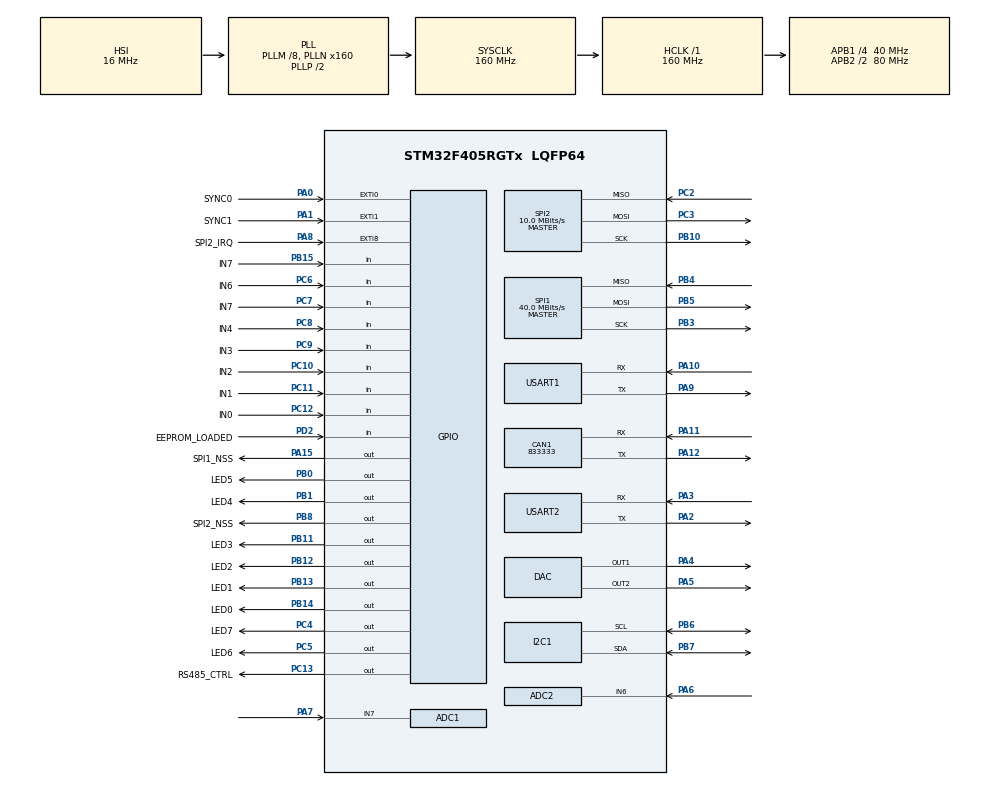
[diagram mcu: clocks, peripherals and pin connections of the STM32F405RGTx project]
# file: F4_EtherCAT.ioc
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ADC1.Channel-0\#ChannelRegularConversion=ADC_CHANNEL_7
ADC1.DMAContinuousRequests=ENABLE
ADC1.ExternalTrigConv=ADC_EXTERNALTRIGCONV_T2_TRGO
ADC1.NbrOfConversionFlag=1
ADC1.Rank-0\#ChannelRegularConversion=1
ADC1.SamplingTime-0\#ChannelRegularConversion=ADC_SAMPLETIME_15CYCLES
ADC1.master=1
ADC2.Channel-0\#ChannelRegularConversion=ADC_CHANNEL_6
ADC2.DMAContinuousRequests=ENABLE
ADC2.ExternalTrigConv=ADC_EXTERNALTRIGCONV_T2_TRGO
ADC2.NbrOfConversionFlag=1
ADC2.Rank-0\#ChannelRegularConversion=1
ADC2.SamplingTime-0\#ChannelRegularConversion=ADC_SAMPLETIME_15CYCLES
CAN1.BS1=CAN_BS1_1TQ
CAN1.BS2=CAN_BS2_1TQ
CAN1.CalculateBaudRate=833333
CAN1.CalculateTimeBit=1200.00
CAN1.CalculateTimeQuantum=400.0
DAC.DAC_Trigger=DAC_TRIGGER_T2_TRGO
DAC.DAC_Trigger2=DAC_TRIGGER_T2_TRGO
Dma.ADC1.0.Direction=DMA_PERIPH_TO_MEMORY
Dma.ADC1.0.FIFOMode=DMA_FIFOMODE_DISABLE
Dma.ADC1.0.Instance=DMA2_Stream0
Dma.ADC1.0.MemDataAlignment=DMA_MDATAALIGN_HALFWORD
Dma.ADC1.0.MemInc=DMA_MINC_ENABLE
Dma.ADC1.0.Mode=DMA_CIRCULAR
Dma.ADC1.0.PeriphDataAlignment=DMA_PDATAALIGN_HALFWORD
Dma.ADC1.0.PeriphInc=DMA_PINC_DISABLE
Dma.ADC1.0.Priority=DMA_PRIORITY_LOW
Dma.ADC2.1.Direction=DMA_PERIPH_TO_MEMORY
Dma.ADC2.1.FIFOMode=DMA_FIFOMODE_DISABLE
Dma.ADC2.1.Instance=DMA2_Stream2
Dma.ADC2.1.MemDataAlignment=DMA_MDATAALIGN_HALFWORD
Dma.ADC2.1.MemInc=DMA_MINC_ENABLE
Dma.ADC2.1.Mode=DMA_CIRCULAR
Dma.ADC2.1.PeriphDataAlignment=DMA_PDATAALIGN_HALFWORD
Dma.ADC2.1.PeriphInc=DMA_PINC_DISABLE
Dma.ADC2.1.Priority=DMA_PRIORITY_LOW
Dma.DAC1.2.Direction=DMA_MEMORY_TO_PERIPH
Dma.DAC1.2.FIFOMode=DMA_FIFOMODE_DISABLE
Dma.DAC1.2.Instance=DMA1_Stream5
Dma.DAC1.2.MemDataAlignment=DMA_MDATAALIGN_HALFWORD
Dma.DAC1.2.MemInc=DMA_MINC_ENABLE
Dma.DAC1.2.Mode=DMA_CIRCULAR
Dma.DAC1.2.PeriphDataAlignment=DMA_PDATAALIGN_HALFWORD
Dma.DAC1.2.PeriphInc=DMA_PINC_DISABLE
Dma.DAC1.2.Priority=DMA_PRIORITY_LOW
Dma.DAC2.3.Direction=DMA_MEMORY_TO_PERIPH
Dma.DAC2.3.FIFOMode=DMA_FIFOMODE_DISABLE
Dma.DAC2.3.Instance=DMA1_Stream6
Dma.DAC2.3.MemDataAlignment=DMA_MDATAALIGN_HALFWORD
Dma.DAC2.3.MemInc=DMA_MINC_ENABLE
Dma.DAC2.3.Mode=DMA_CIRCULAR
Dma.DAC2.3.PeriphDataAlignment=DMA_PDATAALIGN_HALFWORD
Dma.DAC2.3.PeriphInc=DMA_PINC_DISABLE
Dma.DAC2.3.Priority=DMA_PRIORITY_LOW
Dma.Request0=ADC1
Dma.Request1=ADC2
Dma.Request2=DAC1
Dma.Request3=DAC2
Mcu.Family=STM32F4
Mcu.Name=STM32F405RGTx
Mcu.Package=LQFP64
NVIC.DMA1_Stream5_IRQn=true\:0\:0\:false\:false\:true\:false\:true
NVIC.DMA1_Stream6_IRQn=true\:0\:0\:false\:false\:true\:false\:true
NVIC.DMA2_Stream0_IRQn=true\:0\:0\:false\:false\:true\:false\:true
NVIC.DMA2_Stream2_IRQn=true\:0\:0\:false\:false\:true\:false\:true
NVIC.EXTI0_IRQn=true\:0\:0\:false\:false\:false\:true\:true
NVIC.EXTI1_IRQn=true\:0\:0\:false\:false\:false\:true\:true
NVIC.EXTI9_5_IRQn=true\:0\:0\:false\:false\:false\:true\:true
NVIC.PriorityGroup=NVIC_PRIORITYGROUP_4
NVIC.TIM2_IRQn=true\:0\:0\:false\:false\:false\:true\:true
PA0-WKUP.GPIO_Label=SYNC0
PA0-WKUP.GPIO_ModeDefaultEXTI=GPIO_MODE_IT_FALLING
PA0-WKUP.Signal=GPXTI0
PA1.GPIO_Label=SYNC1
PA1.GPIO_ModeDefaultEXTI=GPIO_MODE_IT_FALLING
PA1.Signal=GPXTI1
PA10.Mode=Asynchronous
PA10.Signal=USART1_RX
PA11.Mode=CAN_Activate
PA11.Signal=CAN1_RX
PA12.Mode=CAN_Activate
PA12.Signal=CAN1_TX
PA13.Mode=Serial_Wire
PA13.Signal=SYS_JTMS-SWDIO
PA14.Mode=Serial_Wire
PA14.Signal=SYS_JTCK-SWCLK
PA15.GPIO_Label=SPI1_NSS
PA15.GPIO_Speed=GPIO_SPEED_FREQ_VERY_HIGH
PA15.Signal=GPIO_Output
PA2.Mode=Asynchronous
PA2.Signal=USART2_TX
PA3.Mode=Asynchronous
PA3.Signal=USART2_RX
PA4.Signal=COMP_DAC1_group
PA5.Signal=COMP_DAC2_group
PA6.Signal=ADCx_IN6
PA7.Signal=ADCx_IN7
PA8.GPIO_Label=SPI2_IRQ
PA8.GPIO_ModeDefaultEXTI=GPIO_MODE_IT_FALLING
PA8.Signal=GPXTI8
PA9.Mode=Asynchronous
PA9.Signal=USART1_TX
PB0.GPIO_Label=LED5
PB0.GPIO_Speed=GPIO_SPEED_FREQ_VERY_HIGH
PB0.Signal=GPIO_Output
PB1.GPIO_Label=LED4
PB1.GPIO_Speed=GPIO_SPEED_FREQ_VERY_HIGH
PB1.Signal=GPIO_Output
PB10.Mode=Full_Duplex_Master
PB10.Signal=SPI2_SCK
PB11.GPIO_Label=LED3
PB11.GPIO_Speed=GPIO_SPEED_FREQ_VERY_HIGH
PB11.Signal=GPIO_Output
PB12.GPIO_Label=LED2
PB12.GPIO_Speed=GPIO_SPEED_FREQ_VERY_HIGH
PB12.Signal=GPIO_Output
PB13.GPIO_Label=LED1
PB13.GPIO_Speed=GPIO_SPEED_FREQ_VERY_HIGH
PB13.Signal=GPIO_Output
PB14.GPIO_Label=LED0
PB14.GPIO_Speed=GPIO_SPEED_FREQ_VERY_HIGH
PB14.Signal=GPIO_Output
PB15.GPIO_Label=IN7
PB15.GPIO_PuPd=GPIO_PULLDOWN
PB15.Signal=GPIO_Input
PB3.Mode=Full_Duplex_Master
PB3.Signal=SPI1_SCK
PB4.Mode=Full_Duplex_Master
PB4.Signal=SPI1_MISO
PB5.Mode=Full_Duplex_Master
PB5.Signal=SPI1_MOSI
PB6.Mode=I2C
PB6.Signal=I2C1_SCL
PB7.Mode=I2C
PB7.Signal=I2C1_SDA
PB8.GPIO_Label=SPI2_NSS
PB8.GPIO_Speed=GPIO_SPEED_FREQ_VERY_HIGH
PB8.Signal=GPIO_Output
PC10.GPIO_Label=IN2
PC10.GPIO_PuPd=GPIO_PULLDOWN
PC10.Signal=GPIO_Input
PC11.GPIO_Label=IN1
PC11.GPIO_PuPd=GPIO_PULLDOWN
PC11.Signal=GPIO_Input
PC12.GPIO_Label=IN0
PC12.GPIO_PuPd=GPIO_PULLDOWN
PC12.Signal=GPIO_Input
PC13-ANTI_TAMP.GPIO_Label=RS485_CTRL
PC13-ANTI_TAMP.Signal=GPIO_Output
PC2.Mode=Full_Duplex_Master
PC2.Signal=SPI2_MISO
PC3.Mode=Full_Duplex_Master
PC3.Signal=SPI2_MOSI
PC4.GPIO_Label=LED7
PC4.GPIO_Speed=GPIO_SPEED_FREQ_VERY_HIGH
PC4.Signal=GPIO_Output
PC5.GPIO_Label=LED6
PC5.GPIO_Speed=GPIO_SPEED_FREQ_VERY_HIGH
PC5.Signal=GPIO_Output
PC6.GPIO_Label=IN6
PC6.GPIO_PuPd=GPIO_PULLDOWN
PC6.Signal=GPIO_Input
PC7.GPIO_Label=IN7
PC7.GPIO_PuPd=GPIO_PULLDOWN
PC7.Signal=GPIO_Input
PC8.GPIO_Label=IN4
PC8.GPIO_PuPd=GPIO_PULLDOWN
PC8.Signal=GPIO_Input
PC9.GPIO_Label=IN3
PC9.GPIO_PuPd=GPIO_PULLDOWN
PC9.Signal=GPIO_Input
PD2.GPIO_Label=EEPROM_LOADED
PD2.GPIO_PuPd=GPIO_NOPULL
PD2.Signal=GPIO_Input
PH0-OSC_IN.Mode=HSE-External-Clock-Source
PH0-OSC_IN.Signal=RCC_OSC_IN
PH1-OSC_OUT.Mode=HSE-External-Clock-Source
PH1-OSC_OUT.Signal=RCC_OSC_OUT
ProjectManager.HeapSize=0x200
ProjectManager.StackSize=0x400
ProjectManager.TargetToolchain=STM32CubeIDE
RCC.48MHZClocksFreq_Value=80000000
RCC.AHBFreq_Value=160000000
RCC.APB1CLKDivider=RCC_HCLK_DIV4
RCC.APB1Freq_Value=40000000
RCC.APB1TimFreq_Value=80000000
RCC.APB2CLKDivider=RCC_HCLK_DIV2
RCC.APB2Freq_Value=80000000
RCC.APB2TimFreq_Value=160000000
RCC.CortexFreq_Value=160000000
RCC.HCLKFreq_Value=160000000
RCC.HSE_VALUE=8000000
RCC.HSI_VALUE=16000000
RCC.LSE_VALUE=32768
RCC.PLLM=8
RCC.PLLN=160
RCC.SYSCLKFreq_VALUE=160000000
RCC.SYSCLKSource=RCC_SYSCLKSOURCE_PLLCLK
RCC.VCOOutputFreq_Value=320000000
SH.ADCx_IN6.0=ADC2_IN6,IN6
SH.ADCx_IN7.0=ADC1_IN7,IN7
SH.COMP_DAC1_group.0=DAC_OUT1,DAC_OUT1
SH.COMP_DAC2_group.0=DAC_OUT2,DAC_OUT2
SPI1.CalculateBaudRate=40.0 MBits/s
SPI1.Direction=SPI_DIRECTION_2LINES
SPI1.Mode=SPI_MODE_MASTER
SPI1.VirtualType=VM_MASTER
SPI2.BaudRatePrescaler=SPI_BAUDRATEPRESCALER_4
SPI2.CLKPhase=SPI_PHASE_2EDGE
SPI2.CLKPolarity=SPI_POLARITY_HIGH
SPI2.CalculateBaudRate=10.0 MBits/s
SPI2.Direction=SPI_DIRECTION_2LINES
SPI2.Mode=SPI_MODE_MASTER
SPI2.VirtualType=VM_MASTER
STMicroelectronics.X-CUBE-ALGOBUILD.1.3.0.LibraryCcDSPOoLibraryJjDSPOoLibrary=true
TIM2.AutoReloadPreload=TIM_AUTORELOAD_PRELOAD_ENABLE
TIM2.Period=2000
TIM2.Prescaler=40-1
TIM2.TIM_MasterOutputTrigger=TIM_TRGO_UPDATE
USART1.VirtualMode=VM_ASYNC
USART2.VirtualMode=VM_ASYNC
VP_STMicroelectronics.X-CUBE-ALGOBUILD_VS_DSPOoLibraryJjLibrary_1.3.0_1.3.0.Mode=DSPOoLibraryJjLibrary
VP_TIM2_VS_ClockSourceINT.Mode=Internal
board=custom

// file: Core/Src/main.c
/* USER CODE BEGIN Header */
/**
  ******************************************************************************
  * @file           : main.c
  * @brief          : Main program body
  ******************************************************************************
  * @attention
  *
  * <h2><center>&copy; Copyright (c) 2023 STMicroelectronics.
  * All rights reserved.</center></h2>
  *
  * This software component is licensed by ST under BSD 3-Clause license,
  * the "License"; You may not use this file except in compliance with the
  * License. You may obtain a copy of the License at:
  *                        opensource.org/licenses/BSD-3-Clause
  *
  ******************************************************************************
  */
/* USER CODE END Header */
#include "main.h"

ADC_HandleTypeDef hadc1;
ADC_HandleTypeDef hadc2;
DMA_HandleTypeDef hdma_adc1;
DMA_HandleTypeDef hdma_adc2;

CAN_HandleTypeDef hcan1;

DAC_HandleTypeDef hdac;
DMA_HandleTypeDef hdma_dac1;
DMA_HandleTypeDef hdma_dac2;

I2C_HandleTypeDef hi2c1;

SPI_HandleTypeDef hspi1;
SPI_HandleTypeDef hspi2;

TIM_HandleTypeDef htim2;

UART_HandleTypeDef huart1;
UART_HandleTypeDef huart2;

void SystemClock_Config(void);
static void MX_GPIO_Init(void);
static void MX_DMA_Init(void);
static void MX_I2C1_Init(void);
static void MX_SPI1_Init(void);
static void MX_SPI2_Init(void);
static void MX_DAC_Init(void);
static void MX_ADC1_Init(void);
static void MX_ADC2_Init(void);
static void MX_CAN1_Init(void);
static void MX_USART1_UART_Init(void);
static void MX_USART2_UART_Init(void);
static void MX_TIM2_Init(void);

int main(void)
{

  /* MCU Configuration--------------------------------------------------------*/

  /* Reset of all peripherals, Initializes the Flash interface and the Systick. */
   HAL_Init();

  /* Configure the system clock */
  SystemClock_Config();

  /* Initialize all configured peripherals */
  MX_GPIO_Init();
  MX_DMA_Init();
  MX_I2C1_Init();
  MX_SPI1_Init();
  MX_SPI2_Init();
  MX_DAC_Init();
  MX_ADC1_Init();
  MX_ADC2_Init();
  MX_CAN1_Init();
  MX_USART1_UART_Init();
  MX_USART2_UART_Init();
  MX_TIM2_Init();
  /* USER CODE BEGIN 2 */

  MainCpp();

  /* USER CODE END 2 */

  /* Infinite loop */
  while (1)
  {

  }
}

void SystemClock_Config(void)
{
  RCC_OscInitTypeDef RCC_OscInitStruct = {0};
  RCC_ClkInitTypeDef RCC_ClkInitStruct = {0};

  /** Configure the main internal regulator output voltage
  */
  __HAL_RCC_PWR_CLK_ENABLE();
  __HAL_PWR_VOLTAGESCALING_CONFIG(PWR_REGULATOR_VOLTAGE_SCALE1);
  /** Initializes the RCC Oscillators according to the specified parameters
  * in the RCC_OscInitTypeDef structure.
  */
  RCC_OscInitStruct.OscillatorType = RCC_OSCILLATORTYPE_HSI;
  RCC_OscInitStruct.HSIState = RCC_HSI_ON;
  RCC_OscInitStruct.HSICalibrationValue = RCC_HSICALIBRATION_DEFAULT;
  RCC_OscInitStruct.PLL.PLLState = RCC_PLL_ON;
  RCC_OscInitStruct.PLL.PLLSource = RCC_PLLSOURCE_HSI;
  RCC_OscInitStruct.PLL.PLLM = 8;
  RCC_OscInitStruct.PLL.PLLN = 160;
  RCC_OscInitStruct.PLL.PLLP = RCC_PLLP_DIV2;
  RCC_OscInitStruct.PLL.PLLQ = 4;
  if (HAL_RCC_OscConfig(&RCC_OscInitStruct) != HAL_OK)
  {
    Error_Handler();
  }
  /** Initializes the CPU, AHB and APB buses clocks
  */
  RCC_ClkInitStruct.ClockType = RCC_CLOCKTYPE_HCLK|RCC_CLOCKTYPE_SYSCLK
                              |RCC_CLOCKTYPE_PCLK1|RCC_CLOCKTYPE_PCLK2;
  RCC_ClkInitStruct.SYSCLKSource = RCC_SYSCLKSOURCE_PLLCLK;
  RCC_ClkInitStruct.AHBCLKDivider = RCC_SYSCLK_DIV1;
  RCC_ClkInitStruct.APB1CLKDivider = RCC_HCLK_DIV4;
  RCC_ClkInitStruct.APB2CLKDivider = RCC_HCLK_DIV2;

  if (HAL_RCC_ClockConfig(&RCC_ClkInitStruct, FLASH_LATENCY_5) != HAL_OK)
  {
    Error_Handler();
  }
}

static void MX_ADC1_Init(void)
{

  ADC_ChannelConfTypeDef sConfig = {0};

  /** Configure the global features of the ADC (Clock, Resolution, Data Alignment and number of conversion)
  */
  hadc1.Instance = ADC1;
  hadc1.Init.ClockPrescaler = ADC_CLOCK_SYNC_PCLK_DIV4;
  hadc1.Init.Resolution = ADC_RESOLUTION_12B;
  hadc1.Init.ScanConvMode = DISABLE;
  hadc1.Init.ContinuousConvMode = DISABLE;
  hadc1.Init.DiscontinuousConvMode = DISABLE;
  hadc1.Init.ExternalTrigConvEdge = ADC_EXTERNALTRIGCONVEDGE_RISING;
  hadc1.Init.ExternalTrigConv = ADC_EXTERNALTRIGCONV_T2_TRGO;
  hadc1.Init.DataAlign = ADC_DATAALIGN_RIGHT;
  hadc1.Init.NbrOfConversion = 1;
  hadc1.Init.DMAContinuousRequests = ENABLE;
  hadc1.Init.EOCSelection = ADC_EOC_SINGLE_CONV;
  if (HAL_ADC_Init(&hadc1) != HAL_OK)
  {
    Error_Handler();
  }
  /** Configure for the selected ADC regular channel its corresponding rank in the sequencer and its sample time.
  */
  sConfig.Channel = ADC_CHANNEL_7;
  sConfig.Rank = 1;
  sConfig.SamplingTime = ADC_SAMPLETIME_15CYCLES;
  if (HAL_ADC_ConfigChannel(&hadc1, &sConfig) != HAL_OK)
  {
    Error_Handler();
  }

}

static void MX_ADC2_Init(void)
{

  ADC_ChannelConfTypeDef sConfig = {0};

  /** Configure the global features of the ADC (Clock, Resolution, Data Alignment and number of conversion)
  */
  hadc2.Instance = ADC2;
  hadc2.Init.ClockPrescaler = ADC_CLOCK_SYNC_PCLK_DIV4;
  hadc2.Init.Resolution = ADC_RESOLUTION_12B;
  hadc2.Init.ScanConvMode = DISABLE;
  hadc2.Init.ContinuousConvMode = DISABLE;
  hadc2.Init.DiscontinuousConvMode = DISABLE;
  hadc2.Init.ExternalTrigConvEdge = ADC_EXTERNALTRIGCONVEDGE_RISING;
  hadc2.Init.ExternalTrigConv = ADC_EXTERNALTRIGCONV_T2_TRGO;
  hadc2.Init.DataAlign = ADC_DATAALIGN_RIGHT;
  hadc2.Init.NbrOfConversion = 1;
  hadc2.Init.DMAContinuousRequests = ENABLE;
  hadc2.Init.EOCSelection = ADC_EOC_SINGLE_CONV;
  if (HAL_ADC_Init(&hadc2) != HAL_OK)
  {
    Error_Handler();
  }
  /** Configure for the selected ADC regular channel its corresponding rank in the sequencer and its sample time.
  */
  sConfig.Channel = ADC_CHANNEL_6;
  sConfig.Rank = 1;
  sConfig.SamplingTime = ADC_SAMPLETIME_15CYCLES;
  if (HAL_ADC_ConfigChannel(&hadc2, &sConfig) != HAL_OK)
  {
    Error_Handler();
  }

}

static void MX_CAN1_Init(void)
{

  hcan1.Instance = CAN1;
  hcan1.Init.Prescaler = 16;
  hcan1.Init.Mode = CAN_MODE_NORMAL;
  hcan1.Init.SyncJumpWidth = CAN_SJW_1TQ;
  hcan1.Init.TimeSeg1 = CAN_BS1_1TQ;
  hcan1.Init.TimeSeg2 = CAN_BS2_1TQ;
  hcan1.Init.TimeTriggeredMode = DISABLE;
  hcan1.Init.AutoBusOff = DISABLE;
  hcan1.Init.AutoWakeUp = DISABLE;
  hcan1.Init.AutoRetransmission = DISABLE;
  hcan1.Init.ReceiveFifoLocked = DISABLE;
  hcan1.Init.TransmitFifoPriority = DISABLE;
  if (HAL_CAN_Init(&hcan1) != HAL_OK)
  {
    Error_Handler();
  }

}

static void MX_DAC_Init(void)
{

  DAC_ChannelConfTypeDef sConfig = {0};

  /** DAC Initialization
  */
  hdac.Instance = DAC;
  if (HAL_DAC_Init(&hdac) != HAL_OK)
  {
    Error_Handler();
  }
  /** DAC channel OUT1 config
  */
  sConfig.DAC_Trigger = DAC_TRIGGER_T2_TRGO;
  sConfig.DAC_OutputBuffer = DAC_OUTPUTBUFFER_ENABLE;
  if (HAL_DAC_ConfigChannel(&hdac, &sConfig, DAC_CHANNEL_1) != HAL_OK)
  {
    Error_Handler();
  }
  /** DAC channel OUT2 config
  */
  if (HAL_DAC_ConfigChannel(&hdac, &sConfig, DAC_CHANNEL_2) != HAL_OK)
  {
    Error_Handler();
  }

}

static void MX_I2C1_Init(void)
{

  hi2c1.Instance = I2C1;
  hi2c1.Init.ClockSpeed = 100000;
  hi2c1.Init.DutyCycle = I2C_DUTYCYCLE_2;
  hi2c1.Init.OwnAddress1 = 0;
  hi2c1.Init.AddressingMode = I2C_ADDRESSINGMODE_7BIT;
  hi2c1.Init.DualAddressMode = I2C_DUALADDRESS_DISABLE;
  hi2c1.Init.OwnAddress2 = 0;
  hi2c1.Init.GeneralCallMode = I2C_GENERALCALL_DISABLE;
  hi2c1.Init.NoStretchMode = I2C_NOSTRETCH_DISABLE;
  if (HAL_I2C_Init(&hi2c1) != HAL_OK)
  {
    Error_Handler();
  }

}

static void MX_SPI1_Init(void)
{

  /* SPI1 parameter configuration*/
  hspi1.Instance = SPI1;
  hspi1.Init.Mode = SPI_MODE_MASTER;
  hspi1.Init.Direction = SPI_DIRECTION_2LINES;
  hspi1.Init.DataSize = SPI_DATASIZE_8BIT;
  hspi1.Init.CLKPolarity = SPI_POLARITY_LOW;
  hspi1.Init.CLKPhase = SPI_PHASE_1EDGE;
  hspi1.Init.NSS = SPI_NSS_SOFT;
  hspi1.Init.BaudRatePrescaler = SPI_BAUDRATEPRESCALER_2;
  hspi1.Init.FirstBit = SPI_FIRSTBIT_MSB;
  hspi1.Init.TIMode = SPI_TIMODE_DISABLE;
  hspi1.Init.CRCCalculation = SPI_CRCCALCULATION_DISABLE;
  hspi1.Init.CRCPolynomial = 10;
  if (HAL_SPI_Init(&hspi1) != HAL_OK)
  {
    Error_Handler();
  }

}

static void MX_SPI2_Init(void)
{

  /* SPI2 parameter configuration*/
  hspi2.Instance = SPI2;
  hspi2.Init.Mode = SPI_MODE_MASTER;
  hspi2.Init.Direction = SPI_DIRECTION_2LINES;
  hspi2.Init.DataSize = SPI_DATASIZE_8BIT;
  hspi2.Init.CLKPolarity = SPI_POLARITY_HIGH;
  hspi2.Init.CLKPhase = SPI_PHASE_2EDGE;
  hspi2.Init.NSS = SPI_NSS_SOFT;
  hspi2.Init.BaudRatePrescaler = SPI_BAUDRATEPRESCALER_4;
  hspi2.Init.FirstBit = SPI_FIRSTBIT_MSB;
  hspi2.Init.TIMode = SPI_TIMODE_DISABLE;
  hspi2.Init.CRCCalculation = SPI_CRCCALCULATION_DISABLE;
  hspi2.Init.CRCPolynomial = 10;
  if (HAL_SPI_Init(&hspi2) != HAL_OK)
  {
    Error_Handler();
  }

}

static void MX_TIM2_Init(void)
{

  TIM_ClockConfigTypeDef sClockSourceConfig = {0};
  TIM_MasterConfigTypeDef sMasterConfig = {0};

  htim2.Instance = TIM2;
  htim2.Init.Prescaler = 40-1;
  htim2.Init.CounterMode = TIM_COUNTERMODE_UP;
  htim2.Init.Period = 2000;
  htim2.Init.ClockDivision = TIM_CLOCKDIVISION_DIV1;
  htim2.Init.AutoReloadPreload = TIM_AUTORELOAD_PRELOAD_ENABLE;
  if (HAL_TIM_Base_Init(&htim2) != HAL_OK)
  {
    Error_Handler();
  }
  sClockSourceConfig.ClockSource = TIM_CLOCKSOURCE_INTERNAL;
  if (HAL_TIM_ConfigClockSource(&htim2, &sClockSourceConfig) != HAL_OK)
  {
    Error_Handler();
  }
  sMasterConfig.MasterOutputTrigger = TIM_TRGO_UPDATE;
  sMasterConfig.MasterSlaveMode = TIM_MASTERSLAVEMODE_DISABLE;
  if (HAL_TIMEx_MasterConfigSynchronization(&htim2, &sMasterConfig) != HAL_OK)
  {
    Error_Handler();
  }

}

static void MX_USART1_UART_Init(void)
{

  huart1.Instance = USART1;
  huart1.Init.BaudRate = 115200;
  huart1.Init.WordLength = UART_WORDLENGTH_8B;
  huart1.Init.StopBits = UART_STOPBITS_1;
  huart1.Init.Parity = UART_PARITY_NONE;
  huart1.Init.Mode = UART_MODE_TX_RX;
  huart1.Init.HwFlowCtl = UART_HWCONTROL_NONE;
  huart1.Init.OverSampling = UART_OVERSAMPLING_16;
  if (HAL_UART_Init(&huart1) != HAL_OK)
  {
    Error_Handler();
  }

}

static void MX_USART2_UART_Init(void)
{

  huart2.Instance = USART2;
  huart2.Init.BaudRate = 115200;
  huart2.Init.WordLength = UART_WORDLENGTH_8B;
  huart2.Init.StopBits = UART_STOPBITS_1;
  huart2.Init.Parity = UART_PARITY_NONE;
  huart2.Init.Mode = UART_MODE_TX_RX;
  huart2.Init.HwFlowCtl = UART_HWCONTROL_NONE;
  huart2.Init.OverSampling = UART_OVERSAMPLING_16;
  if (HAL_UART_Init(&huart2) != HAL_OK)
  {
    Error_Handler();
  }

}

static void MX_DMA_Init(void)
{

  /* DMA controller clock enable */
  __HAL_RCC_DMA2_CLK_ENABLE();
  __HAL_RCC_DMA1_CLK_ENABLE();

  /* DMA interrupt init */
  /* DMA1_Stream5_IRQn interrupt configuration */
  HAL_NVIC_SetPriority(DMA1_Stream5_IRQn, 0, 0);
  HAL_NVIC_EnableIRQ(DMA1_Stream5_IRQn);
  /* DMA1_Stream6_IRQn interrupt configuration */
  HAL_NVIC_SetPriority(DMA1_Stream6_IRQn, 0, 0);
  HAL_NVIC_EnableIRQ(DMA1_Stream6_IRQn);
  /* DMA2_Stream0_IRQn interrupt configuration */
  HAL_NVIC_SetPriority(DMA2_Stream0_IRQn, 0, 0);
  HAL_NVIC_EnableIRQ(DMA2_Stream0_IRQn);
  /* DMA2_Stream2_IRQn interrupt configuration */
  HAL_NVIC_SetPriority(DMA2_Stream2_IRQn, 0, 0);
  HAL_NVIC_EnableIRQ(DMA2_Stream2_IRQn);

}

static void MX_GPIO_Init(void)
{
  GPIO_InitTypeDef GPIO_InitStruct = {0};

  /* GPIO Ports Clock Enable */
  __HAL_RCC_GPIOC_CLK_ENABLE();
  __HAL_RCC_GPIOH_CLK_ENABLE();
  __HAL_RCC_GPIOA_CLK_ENABLE();
  __HAL_RCC_GPIOB_CLK_ENABLE();
  __HAL_RCC_GPIOD_CLK_ENABLE();

  /*Configure GPIO pin Output Level */
  HAL_GPIO_WritePin(GPIOC, RS485_CTRL_Pin|LED7_Pin|LED6_Pin, GPIO_PIN_RESET);

  /*Configure GPIO pin Output Level */
  HAL_GPIO_WritePin(GPIOB, LED5_Pin|LED4_Pin|LED3_Pin|LED2_Pin
                          |LED1_Pin|LED0_Pin|SPI2_NSS_Pin, GPIO_PIN_RESET);

  /*Configure GPIO pin Output Level */
  HAL_GPIO_WritePin(SPI1_NSS_GPIO_Port, SPI1_NSS_Pin, GPIO_PIN_RESET);

  /*Configure GPIO pin : RS485_CTRL_Pin */
  GPIO_InitStruct.Pin = RS485_CTRL_Pin;
  GPIO_InitStruct.Mode = GPIO_MODE_OUTPUT_PP;
  GPIO_InitStruct.Pull = GPIO_NOPULL;
  GPIO_InitStruct.Speed = GPIO_SPEED_FREQ_LOW;
  HAL_GPIO_Init(RS485_CTRL_GPIO_Port, &GPIO_InitStruct);

  /*Configure GPIO pins : PC14 PC15 PC0 PC1 */
  GPIO_InitStruct.Pin = GPIO_PIN_14|GPIO_PIN_15|GPIO_PIN_0|GPIO_PIN_1;
  GPIO_InitStruct.Mode = GPIO_MODE_ANALOG;
  GPIO_InitStruct.Pull = GPIO_NOPULL;
  HAL_GPIO_Init(GPIOC, &GPIO_InitStruct);

  /*Configure GPIO pins : SYNC0_Pin SYNC1_Pin SPI2_IRQ_Pin */
  GPIO_InitStruct.Pin = SYNC0_Pin|SYNC1_Pin|SPI2_IRQ_Pin;
  GPIO_InitStruct.Mode = GPIO_MODE_IT_FALLING;
  GPIO_InitStruct.Pull = GPIO_NOPULL;
  HAL_GPIO_Init(GPIOA, &GPIO_InitStruct);

  /*Configure GPIO pins : LED7_Pin LED6_Pin */
  GPIO_InitStruct.Pin = LED7_Pin|LED6_Pin;
  GPIO_InitStruct.Mode = GPIO_MODE_OUTPUT_PP;
  GPIO_InitStruct.Pull = GPIO_NOPULL;
  GPIO_InitStruct.Speed = GPIO_SPEED_FREQ_VERY_HIGH;
  HAL_GPIO_Init(GPIOC, &GPIO_InitStruct);

  /*Configure GPIO pins : LED5_Pin LED4_Pin LED3_Pin LED2_Pin
                           LED1_Pin LED0_Pin SPI2_NSS_Pin */
  GPIO_InitStruct.Pin = LED5_Pin|LED4_Pin|LED3_Pin|LED2_Pin
                          |LED1_Pin|LED0_Pin|SPI2_NSS_Pin;
  GPIO_InitStruct.Mode = GPIO_MODE_OUTPUT_PP;
  GPIO_InitStruct.Pull = GPIO_NOPULL;
  GPIO_InitStruct.Speed = GPIO_SPEED_FREQ_VERY_HIGH;
  HAL_GPIO_Init(GPIOB, &GPIO_InitStruct);

  /*Configure GPIO pins : PB2 PB9 */
  GPIO_InitStruct.Pin = GPIO_PIN_2|GPIO_PIN_9;
  GPIO_InitStruct.Mode = GPIO_MODE_ANALOG;
  GPIO_InitStruct.Pull = GPIO_NOPULL;
  HAL_GPIO_Init(GPIOB, &GPIO_InitStruct);

  /*Configure GPIO pin : IN7_Pin */
  GPIO_InitStruct.Pin = IN7_Pin;
  GPIO_InitStruct.Mode = GPIO_MODE_INPUT;
  GPIO_InitStruct.Pull = GPIO_PULLDOWN;
  HAL_GPIO_Init(IN7_GPIO_Port, &GPIO_InitStruct);

  /*Configure GPIO pins : IN6_Pin IN7C7_Pin IN4_Pin IN3_Pin
                           IN2_Pin IN1_Pin IN0_Pin */
  GPIO_InitStruct.Pin = IN6_Pin|IN7C7_Pin|IN4_Pin|IN3_Pin
                          |IN2_Pin|IN1_Pin|IN0_Pin;
  GPIO_InitStruct.Mode = GPIO_MODE_INPUT;
  GPIO_InitStruct.Pull = GPIO_PULLDOWN;
  HAL_GPIO_Init(GPIOC, &GPIO_InitStruct);

  /*Configure GPIO pin : SPI1_NSS_Pin */
  GPIO_InitStruct.Pin = SPI1_NSS_Pin;
  GPIO_InitStruct.Mode = GPIO_MODE_OUTPUT_PP;
  GPIO_InitStruct.Pull = GPIO_NOPULL;
  GPIO_InitStruct.Speed = GPIO_SPEED_FREQ_VERY_HIGH;
  HAL_GPIO_Init(SPI1_NSS_GPIO_Port, &GPIO_InitStruct);

  /*Configure GPIO pin : EEPROM_LOADED_Pin */
  GPIO_InitStruct.Pin = EEPROM_LOADED_Pin;
  GPIO_InitStruct.Mode = GPIO_MODE_INPUT;
  GPIO_InitStruct.Pull = GPIO_NOPULL;
  HAL_GPIO_Init(EEPROM_LOADED_GPIO_Port, &GPIO_InitStruct);

  /* EXTI interrupt init*/
  HAL_NVIC_SetPriority(EXTI0_IRQn, 0, 0);
  HAL_NVIC_EnableIRQ(EXTI0_IRQn);

  HAL_NVIC_SetPriority(EXTI1_IRQn, 0, 0);
  HAL_NVIC_EnableIRQ(EXTI1_IRQn);

  HAL_NVIC_SetPriority(EXTI9_5_IRQn, 0, 0);
  HAL_NVIC_EnableIRQ(EXTI9_5_IRQn);

}

void Error_Handler(void)
{
  __disable_irq();
  while (1)
  {
  }
}

/************************ (C) COPYRIGHT STMicroelectronics *****END OF FILE****/
